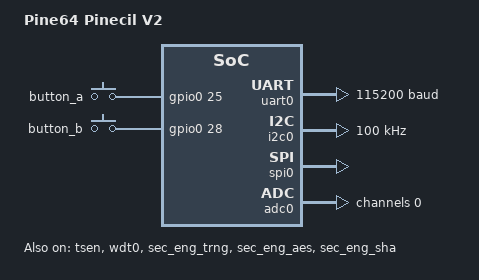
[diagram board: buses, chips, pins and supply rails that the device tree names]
/*
 * SPDX-FileCopyrightText: Copyright The Zephyr Project Contributors
 * SPDX-License-Identifier: Apache-2.0
 */

/dts-v1/;

#include <bflb/bl706.dtsi>
#include "pinecil_v2-pinctrl.dtsi"
#include <zephyr/dt-bindings/adc/adc.h>
#include <zephyr/dt-bindings/input/input-event-codes.h>

/ {
model = "Pine64 Pinecil V2";
compatible = "pine64,pinecil-v2";

chosen {
zephyr,console = &uart0;
zephyr,shell-uart = &uart0;
zephyr,flash = &flash0;
zephyr,code-partition = &slot0_partition;
zephyr,itcm = &itcm;
zephyr,dtcm = &dtcm;
zephyr,sram = &sram0_bt;
zephyr,entropy = &sec_eng_trng;
};

aliases {
sw0 = &button_a;
sw1 = &button_b;
watchdog0 = &wdt0;
die-temp0 = &tsen;
};

buttons {
compatible = "gpio-keys";

button_a: button_a {
gpios = <&gpio0 25 GPIO_ACTIVE_HIGH>;
zephyr,code = <INPUT_KEY_0>;
};

button_b: button_b {
gpios = <&gpio0 28 GPIO_ACTIVE_HIGH>;
zephyr,code = <INPUT_KEY_1>;
};
};
};

&cpu0 {
clock-frequency = <DT_FREQ_M(144)>;
};

&flashctrl {
flash0: flash@23000000 {
compatible = "soc-nv-flash";
reg = <0x23000000 DT_SIZE_M(4)>;
write-block-size = <256>;
erase-block-size = <DT_SIZE_K(4)>;

partitions {
compatible = "fixed-partitions";
#address-cells = <1>;
#size-cells = <1>;

slot0_partition: partition@0 {
label = "image-0";
reg = <0x00000000 DT_SIZE_K(4064)>;
read-only;
};

storage_partition: partition@3f8000 {
label = "storage";
reg = <0x003f8000 DT_SIZE_K(32)>;
};
};
};
};

&gpio0 {
status = "okay";
};

&uart0 {
status = "okay";
current-speed = <115200>;

pinctrl-0 = <&uart0_default>;
pinctrl-names = "default";
};

&i2c0 {
status = "okay";
clock-frequency = <I2C_BITRATE_STANDARD>;

pinctrl-0 = <&i2c0_default>;
pinctrl-names = "default";
};

&spi0 {
status = "okay";

pinctrl-0 = <&spi0_default>;
pinctrl-names = "default";
};

&adc0 {
status = "okay";
pinctrl-0 = <&adc0_default>;
pinctrl-names = "default";

channel@0 {
reg = <0>;
zephyr,gain = "ADC_GAIN_1";
zephyr,reference = "ADC_REF_INTERNAL";
zephyr,acquisition-time = <ADC_ACQ_TIME_DEFAULT>;
zephyr,resolution = <16>;
zephyr,input-positive = <14>;
};
};

&tsen {
status = "okay";
};

&wdt0 {
status = "okay";
};

&sec_eng_trng {
status = "okay";
};

&sec_eng_aes {
status = "okay";
};

&sec_eng_sha {
status = "okay";
};
